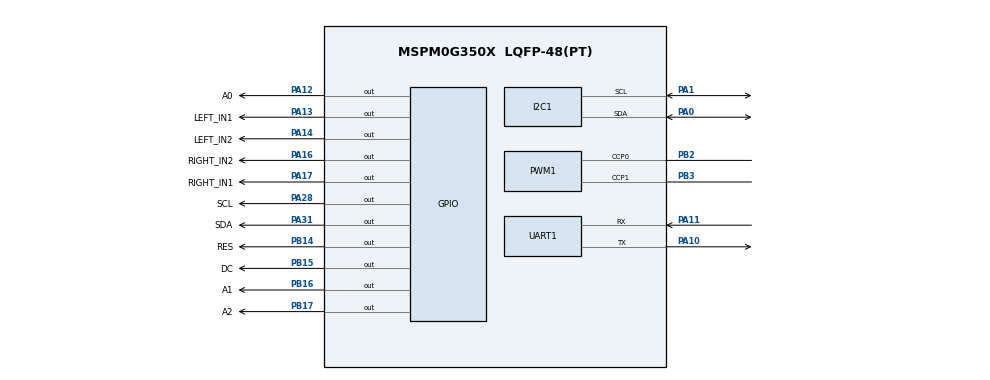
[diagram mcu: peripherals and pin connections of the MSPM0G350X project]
/**
 * @cliArgs --device "MSPM0G350X" --part "Default" --package "LQFP-48(PT)" --product "mspm0_sdk@2.11.00.07"
 * @versions {"tool":"1.26.2+4477"}
 */

/**
 * Import the modules used in this configuration.
 */
const ADC12  = scripting.addModule("/ti/driverlib/ADC12", {}, false);
const ADC121 = ADC12.addInstance();
const GPIO   = scripting.addModule("/ti/driverlib/GPIO", {}, false);
const GPIO1  = GPIO.addInstance();
const GPIO2  = GPIO.addInstance();
const GPIO3  = GPIO.addInstance();
const I2C    = scripting.addModule("/ti/driverlib/I2C", {}, false);
const I2C1   = I2C.addInstance();
const PWM    = scripting.addModule("/ti/driverlib/PWM", {}, false);
const UART   = scripting.addModule("/ti/driverlib/UART", {}, false);
const UART1  = UART.addInstance();
const SYSCTL = scripting.addModule("/ti/driverlib/SYSCTL");

/**
 * Write custom configuration values to the imported modules.
 */
SYSCTL.forceDefaultClkConfig = true;
SYSCTL.clockTreeEn = true;

GPIO1.$name = "MOTOR_DIR";
GPIO1.associatedPins.create(4);

GPIO1.associatedPins[0].$name = "LEFT_IN1";
GPIO1.associatedPins[0].direction = "OUTPUT";
GPIO1.associatedPins[0].initialValue = "CLEARED";
GPIO1.associatedPins[0].pin.$assign = "PA13";

GPIO1.associatedPins[1].$name = "LEFT_IN2";
GPIO1.associatedPins[1].direction = "OUTPUT";
GPIO1.associatedPins[1].initialValue = "SET";
GPIO1.associatedPins[1].pin.$assign = "PA14";

GPIO1.associatedPins[2].$name = "RIGHT_IN1";
GPIO1.associatedPins[2].direction = "OUTPUT";
GPIO1.associatedPins[2].initialValue = "CLEARED";
GPIO1.associatedPins[2].pin.$assign = "PA17";

GPIO1.associatedPins[3].$name = "RIGHT_IN2";
GPIO1.associatedPins[3].direction = "OUTPUT";
GPIO1.associatedPins[3].initialValue = "SET";
GPIO1.associatedPins[3].pin.$assign = "PA16";

GPIO2.$name = "GRAY_ADDR";
GPIO2.associatedPins.create(3);

GPIO2.associatedPins[0].$name = "A0";
GPIO2.associatedPins[0].direction = "OUTPUT";
GPIO2.associatedPins[0].initialValue = "CLEARED";
GPIO2.associatedPins[0].pin.$assign = "PA12";

GPIO2.associatedPins[1].$name = "A1";
GPIO2.associatedPins[1].direction = "OUTPUT";
GPIO2.associatedPins[1].initialValue = "CLEARED";
GPIO2.associatedPins[1].pin.$assign = "PB16";

GPIO2.associatedPins[2].$name = "A2";
GPIO2.associatedPins[2].direction = "OUTPUT";
GPIO2.associatedPins[2].initialValue = "CLEARED";
GPIO2.associatedPins[2].pin.$assign = "PB17";

GPIO3.$name = "OLED";
GPIO3.associatedPins.create(4);

GPIO3.associatedPins[0].$name = "SCL";
GPIO3.associatedPins[0].direction = "OUTPUT";
GPIO3.associatedPins[0].initialValue = "CLEARED";
GPIO3.associatedPins[0].pin.$assign = "PA28";

GPIO3.associatedPins[1].$name = "SDA";
GPIO3.associatedPins[1].direction = "OUTPUT";
GPIO3.associatedPins[1].initialValue = "CLEARED";
GPIO3.associatedPins[1].pin.$assign = "PA31";

GPIO3.associatedPins[2].$name = "RES";
GPIO3.associatedPins[2].direction = "OUTPUT";
GPIO3.associatedPins[2].initialValue = "SET";
GPIO3.associatedPins[2].pin.$assign = "PB14";

GPIO3.associatedPins[3].$name = "DC";
GPIO3.associatedPins[3].direction = "OUTPUT";
GPIO3.associatedPins[3].initialValue = "CLEARED";
GPIO3.associatedPins[3].pin.$assign = "PB15";

I2C1.$name = "I2C_0";
I2C1.basicEnableController = true;
I2C1.basicControllerStandardBusSpeed = "Fast";
I2C1.peripheral.$assign = "I2C0";
I2C1.peripheral.sdaPin.$assign = "PA0";
I2C1.peripheral.sclPin.$assign = "PA1";
I2C1.sdaPinConfig.$name = "ti_driverlib_gpio_GPIOPinGeneric21";
I2C1.sclPinConfig.$name = "ti_driverlib_gpio_GPIOPinGeneric22";

ADC121.$name = "ADC12_0";
ADC121.repeatMode = true;
ADC121.sampleTime0 = "2us";
ADC121.sampClkDiv = "DL_ADC12_CLOCK_DIVIDE_8";
ADC121.enabledInterrupts = ["DL_ADC12_INTERRUPT_MEM0_RESULT_LOADED"];
ADC121.adcMem0_name = "ADC_CH0";
ADC121.peripheral.$assign = "ADC0";
ADC121.peripheral.adcPin0.$assign = "PA27";
ADC121.adcPin0Config.$name = "ti_driverlib_gpio_GPIOPinGeneric20";

const PWM1 = PWM.addInstance();
PWM1.$name = "MOTOR_PWM";
PWM1.timerCount = 500;
PWM1.clockPrescale = 64;
PWM1.ccIndex = [0, 1];
PWM1.dutyArgs = "[0,0,0,0]";
PWM1.pwmMode = "EDGE_ALIGN_UP";
PWM1.peripheral.$assign = "TIMG6";
PWM1.peripheral.ccp0Pin.$assign = "PB2";
PWM1.peripheral.ccp1Pin.$assign = "PB3";
PWM1.PWM_CHANNEL_0.$name = "LEFT_PWM";
PWM1.PWM_CHANNEL_0.dutyCycle = 0;
PWM1.PWM_CHANNEL_1.$name = "RIGHT_PWM";
PWM1.PWM_CHANNEL_1.dutyCycle = 0;

UART1.$name = "UART_0";
UART1.targetBaudRate = 9600;
UART1.peripheral.txPin.$assign = "PA10";
UART1.peripheral.rxPin.$assign = "PA11";
UART1.txPinConfig.$name = "ti_driverlib_gpio_GPIOPinGeneric8";
UART1.rxPinConfig.$name = "ti_driverlib_gpio_GPIOPinGeneric9";

const ProjectConfig              = scripting.addModule("/ti/project_config/ProjectConfig", {}, false);
ProjectConfig.migrationCondition = true;
